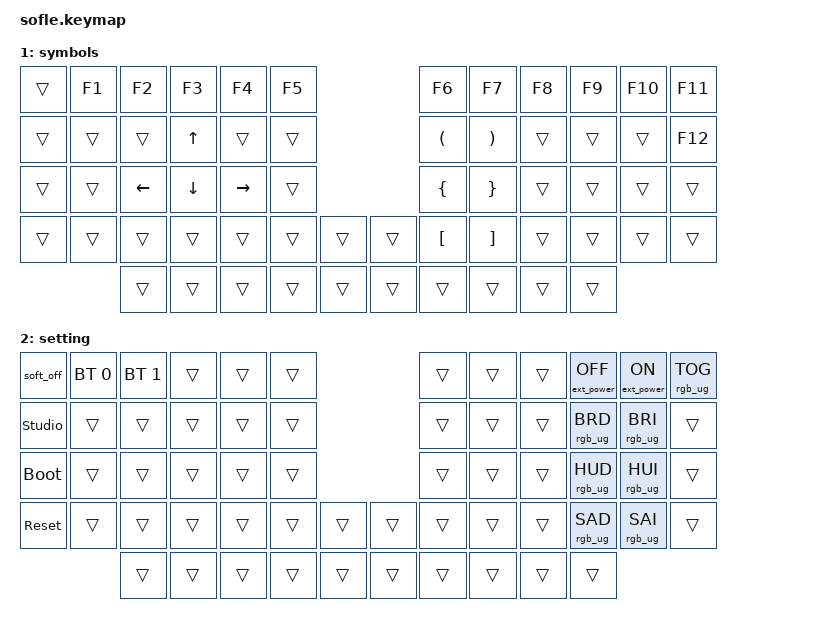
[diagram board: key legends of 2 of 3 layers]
/*
 * Copyright (c) 2020 The ZMK Contributors
 *
 * SPDX-License-Identifier: MIT
 */

#include <behaviors.dtsi>
#include <dt-bindings/zmk/keys.h>
#include <dt-bindings/zmk/bt.h>
#include <dt-bindings/zmk/rgb.h>
#include <dt-bindings/zmk/ext_power.h>

#define BASE 0
#define SYMBOLS 1
#define SETTING 2

/ {

    keymap {
      compatible = "zmk,keymap";

      default_layer {
          display-name = "default";

// ---------------------------------------------------------------------------------------------------------------------------

// |       `       |  1  |  2  |  3   |  4   |  5        |                                   |  6         |   7   |   8   |     9    |   0   |     -     |

// |      TAB      |  Q  |  W  |  E   |  R   |  T        |                                   |  Y         |   U   |   I   |     O    |   P   |     \     |

// |  ESC (SHIFT)  |  A  |  S  |  D   |  F   |  G        |                                   |  H         |   J   |   K   |     L    |   ;   | ' (SHIFT) |

// |               |  Z  |  X  |  C   |  V   |  B        |  MUTE            |  |             |  N         |   M   |   ,   |     .    |   /   |     =     |

//                       |     | ALT  | CTRL | BKSPC (L2)|  ENTER (Symbols) |  | DEL (COMMAND) | SPACE (L2) |       |       |  SETTING |

          bindings = <
&kp GRAVE      &kp N1   &kp N2   &kp N3   &kp N4    &kp N5                                           &kp N6             &kp N7          &kp N8     &kp N9    &kp N0    &kp MINUS
&kp TAB        &kp Q    &kp W    &kp E    &kp R     &kp T                                            &kp Y              &kp U           &kp I      &kp O     &kp P     &kp BSLH
&mt LSHFT ESC  &kp A    &kp S    &kp D    &kp F     &kp G                                            &kp H              &kp J           &kp K      &kp L     &kp SEMI  &mt RSHFT SQT
&none          &kp Z    &kp X    &kp C    &kp V     &kp B           &kp C_MUTE          &none        &kp N              &kp M           &kp COMMA  &kp DOT   &kp FSLH  &kp EQUAL
                        &none    &kp LALT &kp LCTRL &mt LSHFT BSPC  &lt SYMBOLS DEL    &mt LGUI RET  &mt LSHFT SPACE    &mo SYMBOLS     &tog SETTING

          >;

            sensor-bindings = <&inc_dec_kp C_VOL_UP C_VOL_DN &inc_dec_kp PG_UP PG_DN>;
        };

      symbols_layer {

          display-name = "symbols";

// ------------------------------------------------------------------------------------------------------------

// |       |  FN1   |  FN2   |  FN3    |  FN4    |   FN5   |                   |   FN6   |   FN7    |   FN8    |  FN9    |  FN10    |   FN11    |

// |       |        |         |    ^   |         |         |                   |    (    |     )    |          |         |          |   FN12    |

// |       |        |    <-   |    v   |   ->    |         |                   |    {    |     }    |          |         |          |           |

// |       |        |        |         |         |         |        |  |       |    [    |     ]    |          |         |          |           |

//                  |        |         |         |         |        |  |       |         |          |          |         |
          bindings = <
&trans    &kp F1    &kp F2    &kp F3      &kp F4    &kp F5                          &kp F6    &kp F7    &kp F8    &kp F9      &kp F10   &kp F11
&trans    &trans    &trans    &kp UP      &trans    &trans                          &kp LPAR    &kp RPAR    &trans    &trans      &trans    &kp F12
&trans    &trans    &kp LEFT  &kp DOWN    &kp RIGHT &trans                          &kp LBRC    &kp RBRC    &trans    &trans      &trans    &trans
&trans    &trans    &trans    &trans      &trans    &trans    &trans       &trans   &kp LBKT    &kp RBKT    &trans    &trans      &trans    &trans
                    &trans    &trans      &trans    &trans    &trans       &trans   &trans    &trans   &trans    &trans
          >;

          sensor-bindings = <&inc_dec_kp C_VOL_UP C_VOL_DN &inc_dec_kp PG_UP PG_DN>;
      };

      setting_layer {

          display-name = "setting";

// ------------------------------------------------------------------------------------------------------------

// |  OFF   |  BT1   |   BT2   |          |        |         |                   |         |          |          |         |                 |      RGB TOG     |

// | STUDIO |        |         |         |         |         |                   |         |          |          |         |     BRIGHT-     |      BRIGHT+     |

// | RESET  |        |         |         |         |         |                   |         |          |          |         |      HUE-       |       HUE+       |

// | BOOT   |        |         |         |         |         |        |  |       |         |          |          |         |   SATURATION-   |    SATURATION+   |

//                  |         |         |         |         |        |  |       |         |          |          |         |
          bindings = <
&soft_off        &bt BT_SEL 0    &bt BT_SEL 1    &trans      &trans    &trans                           &trans      &trans      &trans    &ext_power EP_OFF  &ext_power EP_ON   &rgb_ug RGB_TOG
&studio_unlock   &trans          &trans          &trans      &trans    &trans                           &trans      &trans      &trans    &rgb_ug RGB_BRD    &rgb_ug RGB_BRI    &trans
&bootloader      &trans          &trans          &trans      &trans    &trans                           &trans      &trans      &trans    &rgb_ug RGB_HUD    &rgb_ug RGB_HUI    &trans
&sys_reset       &trans          &trans          &trans      &trans    &trans    &trans       &trans    &trans      &trans      &trans    &rgb_ug RGB_SAD    &rgb_ug RGB_SAI    &trans
                                 &trans          &trans      &trans    &trans    &trans       &trans    &trans      &trans      &trans    &trans
          >;

          sensor-bindings = <&inc_dec_kp C_VOL_UP C_VOL_DN &inc_dec_kp PG_UP PG_DN>;
      };
    };
};
